# SIMG301M104LIL register map
Vendor: Silicon Labs; Series: Si; File version: B
Registers are 32-bit, read-write, reset 0x0 unless marked. A register's access mark holds for its fields unless they carry their own. Offsets are from the block's base; [hi:lo] are bit positions; {n}, {i} and the like mark numbered series; 'fields as' and 'values as' point back to an identical list.

## PRS_NS — PRS_NS Registers
Base 0x40838000
Same registers: PRS_S 0x50838000
0x00 IPVERSION ro reset 0x9
  [31:0] IPVERSION — IP version ID
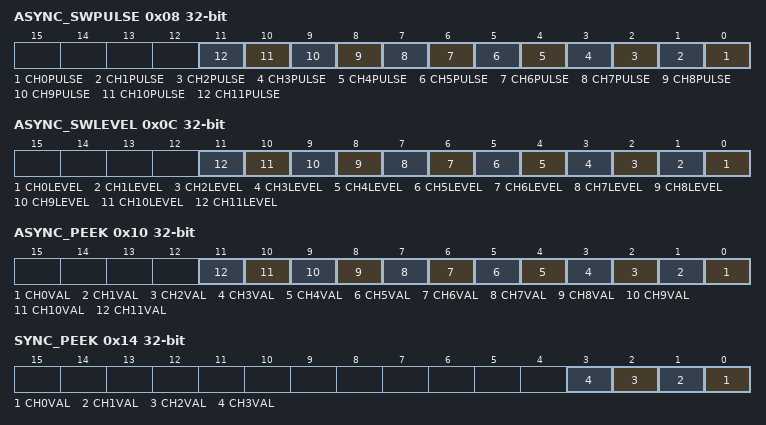
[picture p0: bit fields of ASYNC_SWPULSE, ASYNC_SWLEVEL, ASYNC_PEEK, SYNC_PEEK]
0x08 ASYNC_SWPULSE wo
  [n] CH{n}PULSE (n=0..11) — Channel pulse
0x0C ASYNC_SWLEVEL
  [n] CH{n}LEVEL (n=0..11) — Channel Level
0x10 ASYNC_PEEK ro
  [n] CH{n}VAL (n=0..11) — Channel {n} Current Value
0x14 SYNC_PEEK ro
  [n] CH{n}VAL (n=0..3) — Channel Value
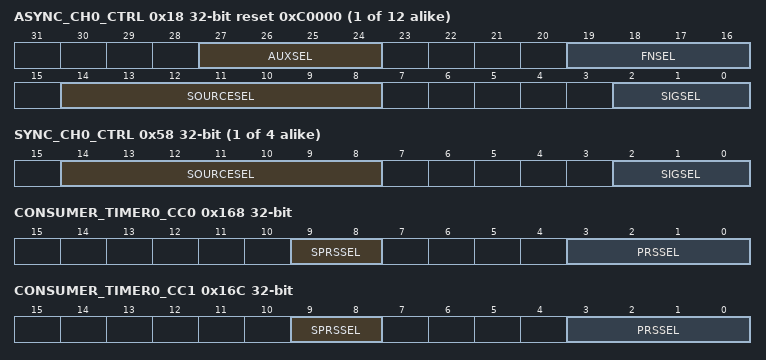
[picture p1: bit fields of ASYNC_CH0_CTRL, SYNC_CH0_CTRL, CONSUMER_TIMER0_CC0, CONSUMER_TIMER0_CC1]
{0x18+4i} ASYNC_CH{i}_CTRL reset 0xC0000 (i=0..11)
  [27:24] AUXSEL — Auxiliary LUT Input Select
  [19:16] FNSEL — Function Select
    0=LOGICAL_ZERO (Logical 0); 1=A_NOR_B; 2=NOT_A_AND_B ((!A) AND B); 3=NOT_A (!A); 4=A_AND_NOT_B (A AND (!B)); 5=NOT_B (!B); 6=A_XOR_B; 7=A_NAND_B; 8=A_AND_B; 9=A_XNOR_B; 10=B; 11=NOT_A_OR_B ((!A) OR B); 12=A; 13=A_OR_NOT_B (A OR (!B)); 14=A_OR_B; 15=LOGICAL_ONE (Logical 1)
  [14:8] SOURCESEL — Source Select
  [2:0] SIGSEL — Signal Select
    0=NONE
{0x58+4i} SYNC_CH{i}_CTRL (i=0..3)
  [14:8] SOURCESEL — Source Select
  [2:0] SIGSEL — Signal Select
    0=NONE
{0x68+0xC*i} CONSUMER_EUSART{i}_CLK (i=0..2) — CLK consumer register
  [3:0] PRSSEL — CLK async channel select
{0x6C+0xC*i} CONSUMER_EUSART{i}_RX (i=0..2) — RX Consumer register
  [3:0] PRSSEL — RX async channel select
{0x70+0xC*i} CONSUMER_EUSART{i}_TRIGGER (i=0..2) — TRIGGER Consumer register
  [3:0] PRSSEL — TRIGGER async channel select
0x8C CONSUMER_FRC_RXRAW — RXRAW consumer register
  [3:0] PRSSEL — RXRAW async channel select
0x90 CONSUMER_CMU_CALDN — CALDN consumer register
  [3:0] PRSSEL — CALDN async channel select
0x94 CONSUMER_CMU_CALUP — CALUP Consumer register
  [3:0] PRSSEL — CALUP async channel select
0x98 CONSUMER_LDMAXBAR0_DMAREQ0 — DMAREQ0 consumer register
  [3:0] PRSSEL — DMAREQ0 async channel select
0x9C CONSUMER_LDMAXBAR0_DMAREQ1 — DMAREQ1 Consumer register
  [3:0] PRSSEL — DMAREQ1 async channel select
0xA0 CONSUMER_LEDDRV0_LEDDRV0ASYNC — LEDDRV0 consumer register
  [3:0] PRSSEL — LEDDRV0 async channel select
0xA4 CONSUMER_LEDDRV0_LEDDRV1ASYNC — LEDDRV1 Consumer register
  [3:0] PRSSEL — LEDDRV1 async channel select
0xA8 CONSUMER_LETIMER0_CLEAR — CLEAR consumer register
  [3:0] PRSSEL — CLEAR async channel select
0xAC CONSUMER_LETIMER0_START — START Consumer register
  [3:0] PRSSEL — START async channel select
0xB0 CONSUMER_LETIMER0_STOP — STOP Consumer register
  [3:0] PRSSEL — STOP async channel select
0xB4 CONSUMER_MODEM_DIN — DIN consumer register
  [3:0] PRSSEL — DIN async channel select
0xB8 CONSUMER_MODEM_PAEN — PAEN Consumer register
  [3:0] PRSSEL — PAEN async channel select
0xBC CONSUMER_PCNT0_S0IN — S0IN consumer register
  [3:0] PRSSEL — S0IN async channel select
0xC0 CONSUMER_PCNT0_S1IN — S1IN Consumer register
  [3:0] PRSSEL — S1IN async channel select
0xC4 CONSUMER_PIXELRZ0_INASYNC — IN consumer register
  [3:0] PRSSEL — IN async channel select
0xC8 CONSUMER_PIXELRZ1_INASYNC — IN consumer register
  [3:0] PRSSEL — IN async channel select
0xF8 CONSUMER_RAC_CLR — CLR consumer register
  [3:0] PRSSEL — CLR async channel select
{0xFC+4i} CONSUMER_RAC_CTIIN{i} (i=0..3) — CTI Consumer register
  [3:0] PRSSEL — CTI async channel select
0x10C CONSUMER_RAC_FORCETX — FORCETX Consumer register
  [3:0] PRSSEL — FORCETX async channel select
0x110 CONSUMER_RAC_RXDIS — RXDIS Consumer register
  [3:0] PRSSEL — RXDIS async channel select
0x114 CONSUMER_RAC_RXEN — RXEN Consumer register
  [3:0] PRSSEL — RXEN async channel select
0x118 CONSUMER_RAC_TXEN — TXEN Consumer register
  [3:0] PRSSEL — TXEN async channel select
0x11C CONSUMER_RFTIMER_PULSE — PULSE consumer register
  [3:0] PRSSEL — PULSE async channel select
0x120 CONSUMER_ADC0_ASYNCSEQ — ASYNC consumer register
  [3:0] PRSSEL — ASYNC async channel select
0x124 CONSUMER_ADC0_SYNCSEQ — SYNC Consumer register
  [9:8] SPRSSEL — SYNC sync channel select
0x128 CONSUMER_SEQACC_WAIT0 — WAIT0 consumer register
  [3:0] PRSSEL — WAIT0 async channel select
{0x128+4i} CONSUMER_SEQACC_WAIT{i} (i=1..3) — WAIT{i} Consumer register
  [3:0] PRSSEL — WAIT{i} async channel select
0x138 CONSUMER_SETAMPER_TAMPERSRC29 — TAMPERSRC29 consumer register
  [3:0] PRSSEL — TAMPERSRC29 async channel select
0x13C CONSUMER_SETAMPER_TAMPERSRC30 — TAMPERSRC30 Consumer register
  [3:0] PRSSEL — TAMPERSRC30 async channel select
0x140 CONSUMER_SETAMPER_TAMPERSRC31 — TAMPERSRC31 Consumer register
  [3:0] PRSSEL — TAMPERSRC31 async channel select
0x144 CONSUMER_SYSRTC0_IN0 — IN0 consumer register
  [3:0] PRSSEL — IN0 async channel select
0x148 CONSUMER_SYSRTC0_IN1 — IN1 Consumer register
  [3:0] PRSSEL — IN1 async channel select
0x14C CONSUMER_HFXO0_OSCREQ — OSC consumer register
  [3:0] PRSSEL — OSC async channel select
0x150 CONSUMER_HFXO0_TIMEOUT — TIMEOUT Consumer register
  [3:0] PRSSEL — TIMEOUT async channel select
0x154 CONSUMER_CORE_CTIIN0 — CTI consumer register
  [3:0] PRSSEL — CTI async channel select
{0x154+4i} CONSUMER_CORE_CTIIN{i} (i=1..3) — CTI Consumer register
  [3:0] PRSSEL — CTI async channel select
0x164 CONSUMER_CORE_M33RXEV — M33 Consumer register
  [3:0] PRSSEL — M33 async channel select
0x168 CONSUMER_TIMER0_CC0 — CC0 consumer register
  [9:8] SPRSSEL — CC0 sync channel select
  [3:0] PRSSEL — CC0 async channel select
0x16C CONSUMER_TIMER0_CC1 — CC1 Consumer register
  [9:8] SPRSSEL — CC1 sync channel select
  [3:0] PRSSEL — CC1 async channel select
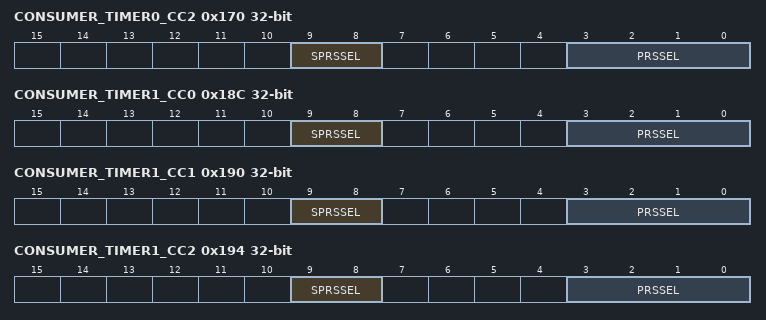
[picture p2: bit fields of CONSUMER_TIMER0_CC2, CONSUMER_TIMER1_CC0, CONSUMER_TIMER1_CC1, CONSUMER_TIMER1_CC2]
0x170 CONSUMER_TIMER0_CC2 — CC2 Consumer register
  [9:8] SPRSSEL — CC2 sync channel select
  [3:0] PRSSEL — CC2 async channel select
0x174 CONSUMER_TIMER0_DTI — DTI Consumer register
  [3:0] PRSSEL — DTI async channel select
0x178 CONSUMER_TIMER0_DTIFS1 — DTI Consumer register
  [3:0] PRSSEL — DTI async channel select
0x17C CONSUMER_TIMER0_DTIFS2 — DTI Consumer register
  [3:0] PRSSEL — DTI async channel select
0x18C CONSUMER_TIMER1_CC0 — CC0 consumer register
  fields as CONSUMER_TIMER0_CC0
0x190 CONSUMER_TIMER1_CC1 — CC1 Consumer register
  fields as CONSUMER_TIMER0_CC1
0x194 CONSUMER_TIMER1_CC2 — CC2 Consumer register
  fields as CONSUMER_TIMER0_CC2
{0x170+0x28*i} CONSUMER_TIMER{i}_DTI (i=1..3) — DTI Consumer register
  [3:0] PRSSEL — DTI async channel select
{0x174+0x28*i} CONSUMER_TIMER{i}_DTIFS1 (i=1..3) — DTI Consumer register
  [3:0] PRSSEL — DTI async channel select
{0x178+0x28*i} CONSUMER_TIMER{i}_DTIFS2 (i=1..3) — DTI Consumer register
  [3:0] PRSSEL — DTI async channel select
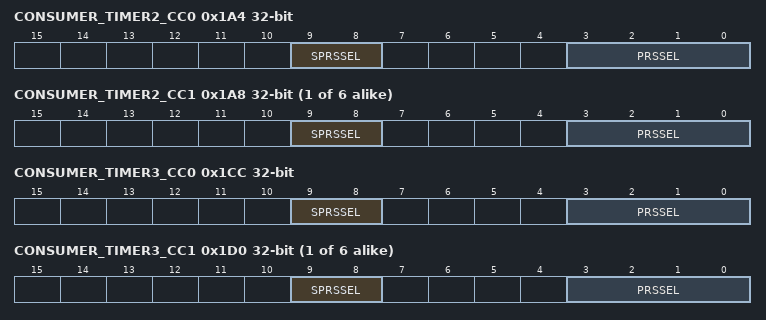
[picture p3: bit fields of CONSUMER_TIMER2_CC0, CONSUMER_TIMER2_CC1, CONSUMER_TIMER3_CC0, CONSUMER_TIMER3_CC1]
0x1A4 CONSUMER_TIMER2_CC0 — CC0 consumer register
  fields as CONSUMER_TIMER0_CC0
{0x1A4+4i} CONSUMER_TIMER2_CC{i} (i=1..6) — CC{i} Consumer register
  [9:8] SPRSSEL — CC{i} sync channel select
  [3:0] PRSSEL — CC{i} async channel select
0x1CC CONSUMER_TIMER3_CC0 — CC0 consumer register
  fields as CONSUMER_TIMER0_CC0
{0x1CC+4i} CONSUMER_TIMER3_CC{i} (i=1..6) — CC{i} Consumer register
  fields as CONSUMER_TIMER2_CC1
0x1F4 CONSUMER_WDOG0_SRC0 — SRC0 consumer register
  [3:0] PRSSEL — SRC0 async channel select
0x1F8 CONSUMER_WDOG0_SRC1 — SRC1 Consumer register
  [3:0] PRSSEL — SRC1 async channel select
0x1FC CONSUMER_WDOG1_SRC0 — SRC0 consumer register
  [3:0] PRSSEL — SRC0 async channel select
0x200 CONSUMER_WDOG1_SRC1 — SRC1 Consumer register
  [3:0] PRSSEL — SRC1 async channel select
0x214 RPURATD4 — Protected register address = (RPURATD register index X 32 + RPURATD bit index) X 4.
  [0] RATDWDOG1SRC1 — WDOG1_SRC1 Protection Bit
